# STM32H533 register map
File version: 1.3
CPU: CM33 r0p0, little endian, MPU, FPU, 4 interrupt priority bits
Registers are 32-bit, read-write, reset 0x0 unless marked. A register's access mark holds for its fields unless they carry their own. Offsets are from the block's base; [hi:lo] are bit positions; {n}, {i} and the like mark numbered series; 'fields as' and 'values as' point back to an identical list.

## PKA — PKA register blank and RAM
Base 0x420C2000
Same registers: PKA_S 0x520C2000
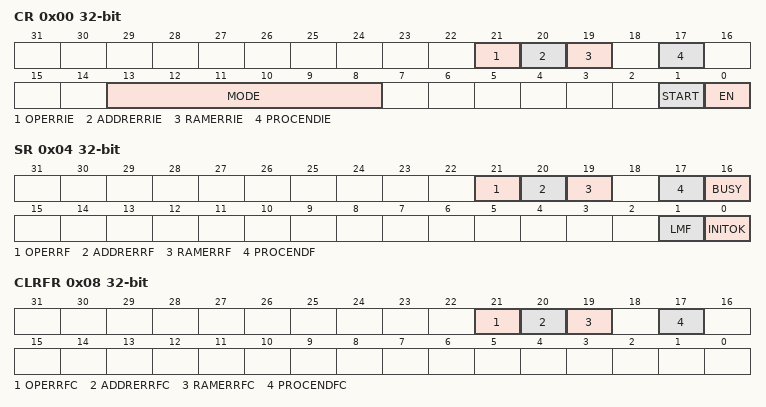
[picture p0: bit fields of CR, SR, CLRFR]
0x00 CR — PKA control register
  [21] OPERRIE — Operation error interrupt enable
  [20] ADDRERRIE — Address error interrupt enable
  [19] RAMERRIE — RAM error interrupt enable
  [17] PROCENDIE — End of operation interrupt enable
  [13:8] MODE — PKA operation code
  [1] START — start the operation
  [0] EN — PKA enable
0x04 SR ro — PKA status register
  [21] OPERRF — Operation error flag
  [20] ADDRERRF — Address error flag
  [19] RAMERRF — PKA RAM error flag
  [17] PROCENDF — PKA end of operation flag
  [16] BUSY — Busy flag
  [1] LMF — Limited mode flag
  [0] INITOK — PKA initialization OK
0x08 CLRFR wo — PKA clear flag register
  [21] OPERRFC — Clear operation error flag
  [20] ADDRERRFC — Clear address error flag
  [19] RAMERRFC — Clear PKA RAM error flag
  [17] PROCENDFC — Clear PKA end of operation flag

## RAMCFG — RAMCFG address block description
Base 0x40026000
Same registers: RAMCFG_S 0x50026000
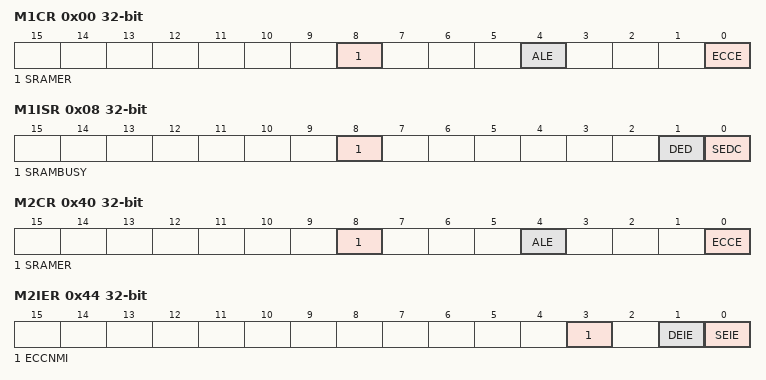
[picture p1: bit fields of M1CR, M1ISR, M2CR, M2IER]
0x00 M1CR (reset mask 0xFFFFFFF0) — RAMCFG memory 1 control register
  [8] SRAMER — SRAM erase
  [4] ALE — Address latch enable
  [0] ECCE — ECC enable.
0x08 M1ISR ro — RAMCFG memory interrupt status register
  [8] SRAMBUSY — SRAM busy with erase operation
  [1] DED — ECC double error detected
  [0] SEDC — ECC single error detected and corrected
0x28 M1ERKEYR wo — RAMCFG memory 1 erase key register
  [7:0] ERASEKEY — Erase write protection key
0x40 M2CR (reset mask 0xFFFFFFF0) — RAMCFG memory 2 control register
  fields as M1CR
0x44 M2IER — RAMCFG memory 2 interrupt enable register
  [3] ECCNMI — Double error NMI
  [1] DEIE — ECC double error interrupt enable
  [0] SEIE — ECC single error interrupt enable
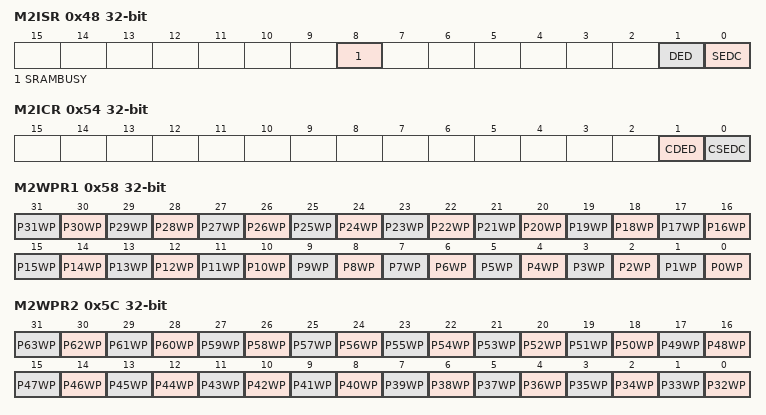
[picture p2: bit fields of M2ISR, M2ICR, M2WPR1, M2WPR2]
0x48 M2ISR ro — RAMCFG memory interrupt status register
  fields as M1ISR
0x4C M2SEAR ro — RAMCFG memory 2 ECC single error address register
  [31:0] ESEA — ECC single error address
0x50 M2DEAR ro — RAMCFG memory 2 ECC double error address register
  [31:0] EDEA — ECC double error address
0x54 M2ICR — RAMCFG memory 2 interrupt clear register 2
  [1] CDED — Clear ECC double error detected
  [0] CSEDC — Clear ECC single error detected and corrected
0x58 M2WPR1 — RAMCFG memory 2 write protection register 1
  [n] P{n}WP (n=0..31) — SRAM2 1-Kbyte page y write protection
0x5C M2WPR2 — RAMCFG memory 2 write protection register 2
  [n-32] P{n}WP (n=32..63) — SRAM2 1-Kbyte page y write protection
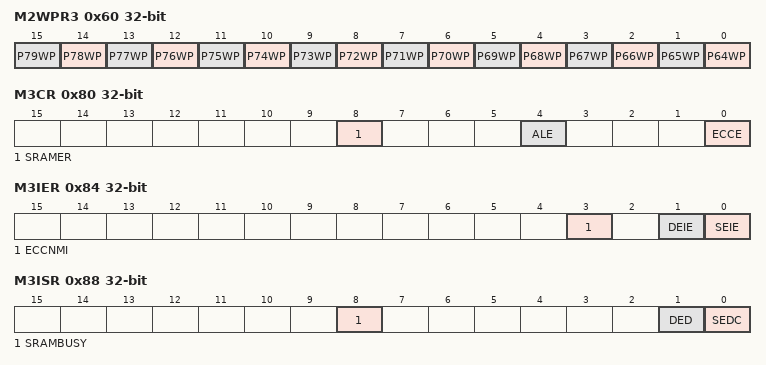
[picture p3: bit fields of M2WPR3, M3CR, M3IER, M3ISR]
0x60 M2WPR3 — RAMCFG memory 2 write protection register 3
  [n-64] P{n}WP (n=64..79) — SRAM2 1-Kbyte page y write protection
0x64 M2ECCKEYR wo — RAMCFG memory 2 ECC key register
  [7:0] ECCKEY — ECC write protection key
0x68 M2ERKEYR wo — RAMCFG memory 2 erase key register
  [7:0] ERASEKEY — Erase write protection key
0x80 M3CR (reset mask 0xFFFFFFF0) — RAMCFG memory 3 control register
  fields as M1CR
0x84 M3IER — RAMCFG memory 3 interrupt enable register
  fields as M2IER
0x88 M3ISR ro — RAMCFG memory interrupt status register
  fields as M1ISR
0x8C M3SEAR ro — RAMCFG memory 3 ECC single error address register
  [31:0] ESEA — ECC single error address
0x90 M3DEAR ro — RAMCFG memory 3 ECC double error address register
  [31:0] EDEA — ECC double error address
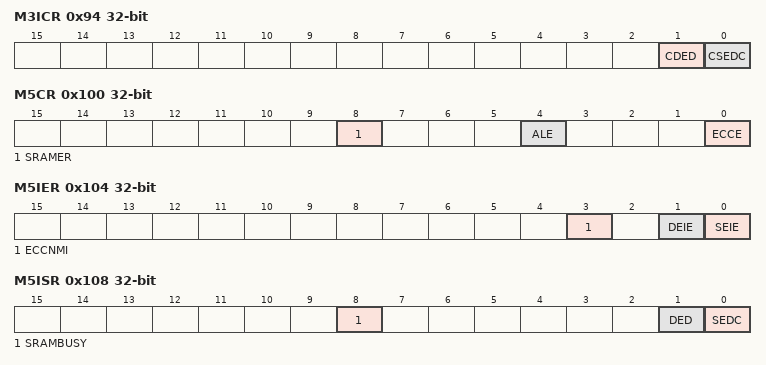
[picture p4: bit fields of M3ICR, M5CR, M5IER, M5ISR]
0x94 M3ICR — RAMCFG memory 3 interrupt clear register 3
  fields as M2ICR
0xA4 M3ECCKEYR wo — RAMCFG memory 3 ECC key register
  [7:0] ECCKEY — ECC write protection key
0xA8 M3ERKEYR wo — RAMCFG memory 3 erase key register
  [7:0] ERASEKEY — Erase write protection key
0xE8 M4ERKEYR wo — RAMCFG memory 4 erase key register
  [7:0] ERASEKEY — Erase write protection key
0x100 M5CR (reset mask 0xFFFFFFF0) — RAMCFG memory 5 control register
  fields as M1CR
0x104 M5IER — RAMCFG memory 5 interrupt enable register
  fields as M2IER
0x108 M5ISR ro — RAMCFG memory interrupt status register
  fields as M1ISR
0x10C M5SEAR ro — RAMCFG memory 5 ECC single error address register
  [31:0] ESEA — ECC single error address
0x110 M5DEAR ro — RAMCFG memory 5 ECC double error address register
  [31:0] EDEA — ECC double error address
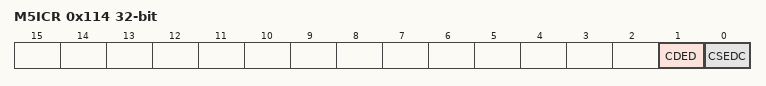
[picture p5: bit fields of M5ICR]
0x114 M5ICR — RAMCFG memory 5 interrupt clear register 5
  fields as M2ICR
0x124 M5ECCKEYR wo — RAMCFG memory 5 ECC key register
  [7:0] ECCKEY — ECC write protection key
0x128 M5ERKEYR wo — RAMCFG memory 5 erase key register
  [7:0] ERASEKEY — Erase write protection key
